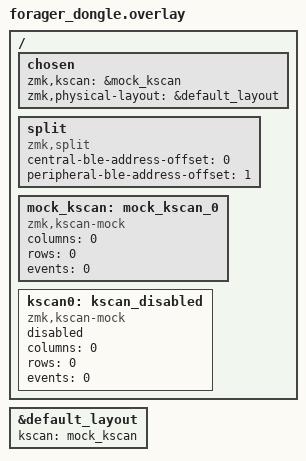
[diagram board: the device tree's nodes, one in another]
#include "forager.dtsi"  // This includes the default_layout definition

// Delete the problematic kscan from dtsi
/delete-node/ &kscan0;

/ {
    chosen {
        zmk,kscan = &mock_kscan;
        zmk,physical-layout = &default_layout;  // Use default_layout, not physical_layout
    };
    
    // Split configuration for dongle (central)
    split: split {
        compatible = "zmk,split";
        central-ble-address-offset = <0>;      // Dongle = address 0
        peripheral-ble-address-offset = <1>;   // Base offset for peripherals
    };
    
    // Create new mock kscan for dongle
    mock_kscan: mock_kscan_0 {
        compatible = "zmk,kscan-mock";
        columns = <0>;
        rows = <0>;
        events = <0>;
    };
    
    // Create a new kscan0 that's disabled (in case other overlays reference it)
    kscan0: kscan_disabled {
        compatible = "zmk,kscan-mock";
        columns = <0>;
        rows = <0>;
        events = <0>;
        status = "disabled";
    };
};

// Update the default layout to use mock kscan for dongle
&default_layout {
    kscan = <&mock_kscan>;  // Change from the matrix kscan to mock kscan
};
